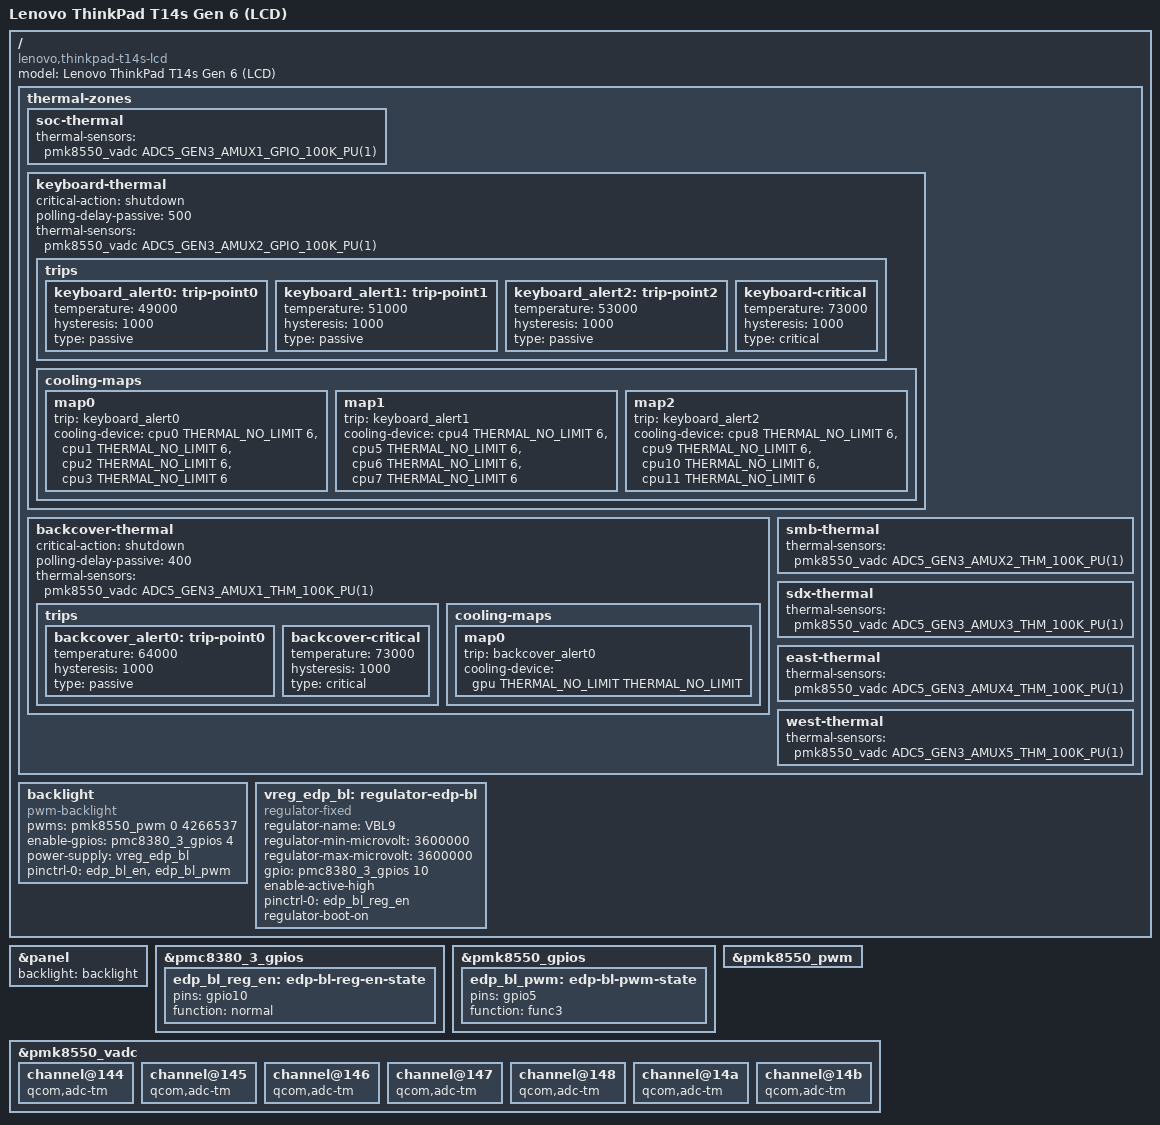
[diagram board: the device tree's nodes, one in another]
// SPDX-License-Identifier: BSD-3-Clause
/*
 * Copyright (c) 2025, Linaro Limited
 */

#include "x1e78100-lenovo-thinkpad-t14s.dtsi"

/ {
	model = "Lenovo ThinkPad T14s Gen 6 (LCD)";
	compatible = "lenovo,thinkpad-t14s-lcd", "lenovo,thinkpad-t14s",
		     "qcom,x1e78100", "qcom,x1e80100";

	thermal-zones {
		soc-thermal {
			thermal-sensors = <&pmk8550_vadc ADC5_GEN3_AMUX1_GPIO_100K_PU(1)>;
		};

		keyboard-thermal {
			critical-action = "shutdown";
			polling-delay-passive = <500>;

			thermal-sensors = <&pmk8550_vadc ADC5_GEN3_AMUX2_GPIO_100K_PU(1)>;

			trips {

				keyboard_alert0: trip-point0 {
					temperature = <49000>;
					hysteresis = <1000>;
					type = "passive";
				};

				keyboard_alert1: trip-point1 {
					temperature = <51000>;
					hysteresis = <1000>;
					type = "passive";
				};

				keyboard_alert2: trip-point2 {
					temperature = <53000>;
					hysteresis = <1000>;
					type = "passive";
				};

				keyboard-critical {
					temperature = <73000>;
					hysteresis = <1000>;
					type = "critical";
				};
			};

			cooling-maps {
				map0 {
					trip = <&keyboard_alert0>;
					cooling-device = <&cpu0 THERMAL_NO_LIMIT 6>,
							 <&cpu1 THERMAL_NO_LIMIT 6>,
							 <&cpu2 THERMAL_NO_LIMIT 6>,
							 <&cpu3 THERMAL_NO_LIMIT 6>;
				};

				map1 {
					trip = <&keyboard_alert1>;
					cooling-device = <&cpu4 THERMAL_NO_LIMIT 6>,
							 <&cpu5 THERMAL_NO_LIMIT 6>,
							 <&cpu6 THERMAL_NO_LIMIT 6>,
							 <&cpu7 THERMAL_NO_LIMIT 6>;
				};

				map2 {
					trip = <&keyboard_alert2>;
					cooling-device = <&cpu8 THERMAL_NO_LIMIT 6>,
							 <&cpu9 THERMAL_NO_LIMIT 6>,
							 <&cpu10 THERMAL_NO_LIMIT 6>,
							 <&cpu11 THERMAL_NO_LIMIT 6>;

				};
			};
		};

		backcover-thermal {
			critical-action = "shutdown";
			polling-delay-passive = <400>;

			thermal-sensors = <&pmk8550_vadc ADC5_GEN3_AMUX1_THM_100K_PU(1)>;

			trips {
				backcover_alert0: trip-point0 {
					temperature = <64000>;
					hysteresis = <1000>;
					type = "passive";
				};

				backcover-critical {
					temperature = <73000>;
					hysteresis = <1000>;
					type = "critical";
				};
			};

			cooling-maps {
				map0 {
					trip = <&backcover_alert0>;
					cooling-device = <&gpu THERMAL_NO_LIMIT THERMAL_NO_LIMIT>;
				};
			};
		};

		smb-thermal {
			thermal-sensors = <&pmk8550_vadc ADC5_GEN3_AMUX2_THM_100K_PU(1)>;
		};

		sdx-thermal {
			thermal-sensors = <&pmk8550_vadc ADC5_GEN3_AMUX3_THM_100K_PU(1)>;
		};

		east-thermal {
			thermal-sensors = <&pmk8550_vadc ADC5_GEN3_AMUX4_THM_100K_PU(1)>;
		};

		west-thermal {
			thermal-sensors = <&pmk8550_vadc ADC5_GEN3_AMUX5_THM_100K_PU(1)>;
		};
	};

	backlight: backlight {
		compatible = "pwm-backlight";
		pwms = <&pmk8550_pwm 0 4266537>;
		enable-gpios = <&pmc8380_3_gpios 4 GPIO_ACTIVE_HIGH>;
		power-supply = <&vreg_edp_bl>;

		pinctrl-0 = <&edp_bl_en>, <&edp_bl_pwm>;
		pinctrl-names = "default";
	};

	vreg_edp_bl: regulator-edp-bl {
		compatible = "regulator-fixed";

		regulator-name = "VBL9";
		regulator-min-microvolt = <3600000>;
		regulator-max-microvolt = <3600000>;

		gpio = <&pmc8380_3_gpios 10 GPIO_ACTIVE_HIGH>;
		enable-active-high;

		pinctrl-names = "default";
		pinctrl-0 = <&edp_bl_reg_en>;

		regulator-boot-on;
	};

};

&panel {
	backlight = <&backlight>;
};

&pmc8380_3_gpios {
	edp_bl_reg_en: edp-bl-reg-en-state {
		pins = "gpio10";
		function = "normal";
	};
};

&pmk8550_gpios {
	edp_bl_pwm: edp-bl-pwm-state {
		pins = "gpio5";
		function = "func3";
	};
};

&pmk8550_pwm {
	status = "okay";
};

&pmk8550_vadc {
	channel@144 {
		qcom,adc-tm;
	};

	channel@145 {
		qcom,adc-tm;
	};

	channel@146 {
		qcom,adc-tm;
	};

	channel@147 {
		qcom,adc-tm;
	};

	channel@148 {
		qcom,adc-tm;
	};

	channel@14a {
		qcom,adc-tm;
	};

	channel@14b {
		qcom,adc-tm;
	};
};
